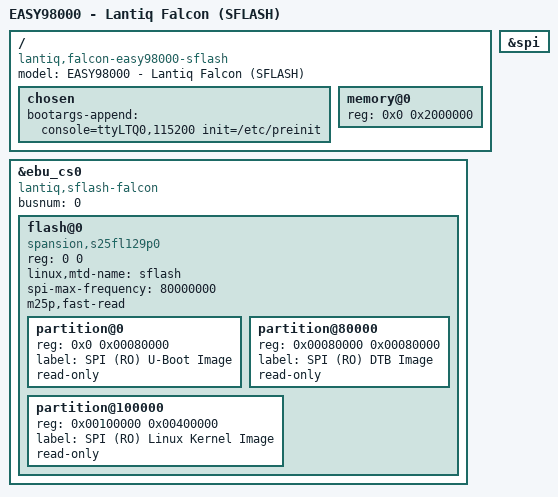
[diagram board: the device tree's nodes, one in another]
/dts-v1/;

/include/ "falcon.dtsi"

/ {
	model = "EASY98000 - Lantiq Falcon (SFLASH)";
	compatible = "lantiq,falcon-easy98000-sflash", "lantiq,falcon-easy98000", "lantiq,falcon";

	chosen {
		bootargs-append = "console=ttyLTQ0,115200 init=/etc/preinit";
	};

	memory@0 {
		reg = <0x0 0x2000000>;
	};
};

&ebu_cs0 {
	#address-cells = <1>;
	#size-cells = <1>;
	compatible = "lantiq,sflash-falcon", "simple-bus";
	busnum = <0>;

	flash@0 {
		#address-cells = <1>;
		#size-cells = <1>;
		compatible = "spansion,s25fl129p0";
		reg = <0 0>;
		linux,mtd-name = "sflash";
		spi-max-frequency = <80000000>;
		m25p,fast-read;

		partition@0 {
			reg = <0x0 0x00080000>;
			label = "SPI (RO) U-Boot Image";
			read-only;
		};

		partition@80000 {
			reg = <0x00080000 0x00080000>;
			label = "SPI (RO) DTB Image";
			read-only;
		};

		partition@100000 {
			reg = <0x00100000 0x00400000>;
			label = "SPI (RO) Linux Kernel Image";
			read-only;
		};
	};
};

&spi {
	status = "okay";
};
